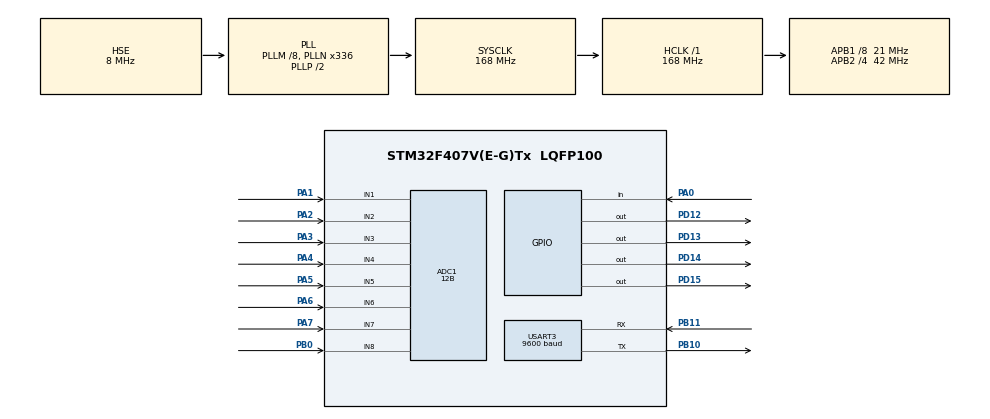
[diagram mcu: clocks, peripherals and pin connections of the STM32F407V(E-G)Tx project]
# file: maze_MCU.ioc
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ADC1.Channel-0\#ChannelRegularConversion=ADC_CHANNEL_1
ADC1.Channel-1\#ChannelRegularConversion=ADC_CHANNEL_2
ADC1.Channel-10\#ChannelRegularConversion=ADC_CHANNEL_6
ADC1.Channel-11\#ChannelRegularConversion=ADC_CHANNEL_7
ADC1.Channel-12\#ChannelRegularConversion=ADC_CHANNEL_8
ADC1.Channel-14\#ChannelRegularConversion=ADC_CHANNEL_1
ADC1.Channel-15\#ChannelRegularConversion=ADC_CHANNEL_1
ADC1.Channel-16\#ChannelRegularConversion=ADC_CHANNEL_1
ADC1.Channel-17\#ChannelRegularConversion=ADC_CHANNEL_1
ADC1.Channel-18\#ChannelRegularConversion=ADC_CHANNEL_1
ADC1.Channel-19\#ChannelRegularConversion=ADC_CHANNEL_1
ADC1.Channel-2\#ChannelRegularConversion=ADC_CHANNEL_3
ADC1.Channel-20\#ChannelRegularConversion=ADC_CHANNEL_1
ADC1.Channel-21\#ChannelRegularConversion=ADC_CHANNEL_1
ADC1.Channel-22\#ChannelRegularConversion=ADC_CHANNEL_1
ADC1.Channel-23\#ChannelRegularConversion=ADC_CHANNEL_1
ADC1.Channel-8\#ChannelRegularConversion=ADC_CHANNEL_4
ADC1.Channel-9\#ChannelRegularConversion=ADC_CHANNEL_5
ADC1.ClockPrescaler=ADC_CLOCK_SYNC_PCLK_DIV2
ADC1.ContinuousConvMode=ENABLE
ADC1.DMAContinuousRequests=ENABLE
ADC1.DataAlign=ADC_DATAALIGN_RIGHT
ADC1.DiscontinuousConvMode=DISABLE
ADC1.EOCSelection=ADC_EOC_SEQ_CONV
ADC1.EnableAnalogWatchDog=false
ADC1.ExternalTrigConv=ADC_SOFTWARE_START
ADC1.ExternalTrigConvEdge=ADC_EXTERNALTRIGCONVEDGE_NONE
ADC1.InjNumberOfConversion=0
ADC1.NbrOfConversion=8
ADC1.NbrOfConversionFlag=1
ADC1.Rank-0\#ChannelRegularConversion=1
ADC1.Rank-1\#ChannelRegularConversion=2
ADC1.Rank-10\#ChannelRegularConversion=6
ADC1.Rank-11\#ChannelRegularConversion=7
ADC1.Rank-12\#ChannelRegularConversion=8
ADC1.Rank-14\#ChannelRegularConversion=8
ADC1.Rank-15\#ChannelRegularConversion=9
ADC1.Rank-16\#ChannelRegularConversion=9
ADC1.Rank-17\#ChannelRegularConversion=10
ADC1.Rank-18\#ChannelRegularConversion=11
ADC1.Rank-19\#ChannelRegularConversion=12
ADC1.Rank-2\#ChannelRegularConversion=3
ADC1.Rank-20\#ChannelRegularConversion=13
ADC1.Rank-21\#ChannelRegularConversion=14
ADC1.Rank-22\#ChannelRegularConversion=15
ADC1.Rank-23\#ChannelRegularConversion=16
ADC1.Rank-8\#ChannelRegularConversion=4
ADC1.Rank-9\#ChannelRegularConversion=5
ADC1.Resolution=ADC_RESOLUTION_12B
ADC1.SamplingTime-0\#ChannelRegularConversion=ADC_SAMPLETIME_84CYCLES
ADC1.SamplingTime-1\#ChannelRegularConversion=ADC_SAMPLETIME_84CYCLES
ADC1.SamplingTime-10\#ChannelRegularConversion=ADC_SAMPLETIME_84CYCLES
ADC1.SamplingTime-11\#ChannelRegularConversion=ADC_SAMPLETIME_84CYCLES
ADC1.SamplingTime-12\#ChannelRegularConversion=ADC_SAMPLETIME_84CYCLES
ADC1.SamplingTime-14\#ChannelRegularConversion=ADC_SAMPLETIME_3CYCLES
ADC1.SamplingTime-15\#ChannelRegularConversion=ADC_SAMPLETIME_3CYCLES
ADC1.SamplingTime-16\#ChannelRegularConversion=ADC_SAMPLETIME_3CYCLES
ADC1.SamplingTime-17\#ChannelRegularConversion=ADC_SAMPLETIME_3CYCLES
ADC1.SamplingTime-18\#ChannelRegularConversion=ADC_SAMPLETIME_3CYCLES
ADC1.SamplingTime-19\#ChannelRegularConversion=ADC_SAMPLETIME_3CYCLES
ADC1.SamplingTime-2\#ChannelRegularConversion=ADC_SAMPLETIME_84CYCLES
ADC1.SamplingTime-20\#ChannelRegularConversion=ADC_SAMPLETIME_3CYCLES
ADC1.SamplingTime-21\#ChannelRegularConversion=ADC_SAMPLETIME_3CYCLES
ADC1.SamplingTime-22\#ChannelRegularConversion=ADC_SAMPLETIME_3CYCLES
ADC1.SamplingTime-23\#ChannelRegularConversion=ADC_SAMPLETIME_3CYCLES
ADC1.SamplingTime-8\#ChannelRegularConversion=ADC_SAMPLETIME_84CYCLES
ADC1.SamplingTime-9\#ChannelRegularConversion=ADC_SAMPLETIME_84CYCLES
ADC1.ScanConvMode=ENABLE
ADC1.master=1
Dma.ADC1.0.Direction=DMA_PERIPH_TO_MEMORY
Dma.ADC1.0.FIFOMode=DMA_FIFOMODE_DISABLE
Dma.ADC1.0.Instance=DMA2_Stream0
Dma.ADC1.0.MemDataAlignment=DMA_MDATAALIGN_WORD
Dma.ADC1.0.MemInc=DMA_MINC_ENABLE
Dma.ADC1.0.Mode=DMA_CIRCULAR
Dma.ADC1.0.PeriphDataAlignment=DMA_PDATAALIGN_WORD
Dma.ADC1.0.PeriphInc=DMA_PINC_DISABLE
Dma.ADC1.0.Priority=DMA_PRIORITY_LOW
Dma.Request0=ADC1
Mcu.Family=STM32F4
Mcu.Name=STM32F407V(E-G)Tx
Mcu.Package=LQFP100
NVIC.ADC_IRQn=true\:0\:0\:false\:false\:true\:true
NVIC.DMA2_Stream0_IRQn=true\:0\:0\:false\:false\:true\:false
NVIC.PriorityGroup=NVIC_PRIORITYGROUP_4
NVIC.USART3_IRQn=true\:0\:0\:false\:false\:true\:true
PA0-WKUP.Signal=GPIO_Input
PA1.Signal=ADCx_IN1
PA2.Signal=ADCx_IN2
PA3.Signal=ADCx_IN3
PA4.Signal=ADCx_IN4
PA5.Signal=ADCx_IN5
PA6.Signal=ADCx_IN6
PA7.Signal=ADCx_IN7
PB0.Signal=ADCx_IN8
PB10.Mode=Asynchronous
PB10.Signal=USART3_TX
PB11.Mode=Asynchronous
PB11.Signal=USART3_RX
PD12.Signal=GPIO_Output
PD13.Signal=GPIO_Output
PD14.Signal=GPIO_Output
PD15.Signal=GPIO_Output
PH0-OSC_IN.Mode=HSE-External-Oscillator
PH0-OSC_IN.Signal=RCC_OSC_IN
PH1-OSC_OUT.Mode=HSE-External-Oscillator
PH1-OSC_OUT.Signal=RCC_OSC_OUT
ProjectManager.HeapSize=0x200
ProjectManager.StackSize=0x400
ProjectManager.TargetToolchain=MDK-ARM V5
RCC.48MHZClocksFreq_Value=84000000
RCC.AHBFreq_Value=168000000
RCC.APB1CLKDivider=RCC_HCLK_DIV8
RCC.APB1Freq_Value=21000000
RCC.APB1TimFreq_Value=42000000
RCC.APB2CLKDivider=RCC_HCLK_DIV4
RCC.APB2Freq_Value=42000000
RCC.APB2TimFreq_Value=84000000
RCC.CortexFreq_Value=168000000
RCC.HCLKFreq_Value=168000000
RCC.HSE_VALUE=8000000
RCC.HSI_VALUE=16000000
RCC.LSE_VALUE=32768
RCC.PLLM=8
RCC.PLLN=336
RCC.PLLSourceVirtual=RCC_PLLSOURCE_HSE
RCC.SYSCLKFreq_VALUE=168000000
RCC.SYSCLKSource=RCC_SYSCLKSOURCE_PLLCLK
RCC.VCOOutputFreq_Value=336000000
SH.ADCx_IN1.0=ADC1_IN1,IN1
SH.ADCx_IN2.0=ADC1_IN2,IN2
SH.ADCx_IN3.0=ADC1_IN3,IN3
SH.ADCx_IN4.0=ADC1_IN4,IN4
SH.ADCx_IN5.0=ADC1_IN5,IN5
SH.ADCx_IN6.0=ADC1_IN6,IN6
SH.ADCx_IN7.0=ADC1_IN7,IN7
SH.ADCx_IN8.0=ADC1_IN8,IN8
USART3.BaudRate=9600
USART3.VirtualMode=VM_ASYNC
board=maze_MCU

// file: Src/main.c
/**
  ******************************************************************************
  * @file           : main.c
  * @brief          : Main program body
  ******************************************************************************
  ** This notice applies to any and all portions of this file
  * that are not between comment pairs USER CODE BEGIN and
  * USER CODE END. Other portions of this file, whether
  * inserted by the user or by software development tools
  * are owned by their respective copyright owners.
  *
  * COPYRIGHT(c) 2018 STMicroelectronics
  *
  * Redistribution and use in source and binary forms, with or without modification,
  * are permitted provided that the following conditions are met:
  *   1. Redistributions of source code must retain the above copyright notice,
  *      this list of conditions and the following disclaimer.
  *   2. Redistributions in binary form must reproduce the above copyright notice,
  *      this list of conditions and the following disclaimer in the documentation
  *      and/or other materials provided with the distribution.
  *   3. Neither the name of STMicroelectronics nor the names of its contributors
  *      may be used to endorse or promote products derived from this software
  *      without specific prior written permission.
  *
  * THIS SOFTWARE IS PROVIDED BY THE COPYRIGHT HOLDERS AND CONTRIBUTORS "AS IS"
  * AND ANY EXPRESS OR IMPLIED WARRANTIES, INCLUDING, BUT NOT LIMITED TO, THE
  * IMPLIED WARRANTIES OF MERCHANTABILITY AND FITNESS FOR A PARTICULAR PURPOSE ARE
  * DISCLAIMED. IN NO EVENT SHALL THE COPYRIGHT HOLDER OR CONTRIBUTORS BE LIABLE
  * FOR ANY DIRECT, INDIRECT, INCIDENTAL, SPECIAL, EXEMPLARY, OR CONSEQUENTIAL
  * DAMAGES (INCLUDING, BUT NOT LIMITED TO, PROCUREMENT OF SUBSTITUTE GOODS OR
  * SERVICES; LOSS OF USE, DATA, OR PROFITS; OR BUSINESS INTERRUPTION) HOWEVER
  * CAUSED AND ON ANY THEORY OF LIABILITY, WHETHER IN CONTRACT, STRICT LIABILITY,
  * OR TORT (INCLUDING NEGLIGENCE OR OTHERWISE) ARISING IN ANY WAY OUT OF THE USE
  * OF THIS SOFTWARE, EVEN IF ADVISED OF THE POSSIBILITY OF SUCH DAMAGE.
  *
  ******************************************************************************
  */

/* 1.
 *
 */
/* 1. white and dark object has ~4 units difference of reflection.
 *
 */
#include "main.h"
#include "stm32f4xx_hal.h"

#define SysTickIT_500us 2000

/* USER CODE BEGIN Includes */
#include "maze.h"
#include "esp8266.h"
#include "uart_maze.h"
/* USER CODE END Includes */
int g_test;
ADC_HandleTypeDef hadc1;
DMA_HandleTypeDef hdma_adc1;
UART_HandleTypeDef huart3;

/* USER CODE BEGIN PV */
/* Private variables ---------------------------------------------------------*/
//bool calibrating = true;
__IO uint32_t ADC_BUF[8];
__IO uint8_t chIndex = 0;
__IO UART UART_esp8266 = {STANDBY, &huart3, INIT, 0, 0, NO};
/* USER CODE END PV */

void SystemClock_Config(void);
static void MX_GPIO_Init(void);
static void MX_USART3_UART_Init(void);
static void MX_ADC1_Init(void);

/* USER CODE BEGIN PFP */
/* Private function prototypes -----------------------------------------------*/

/* USER CODE END PFP */

/* USER CODE BEGIN 0 */
void HAL_ADC_ConvCpltCallback(ADC_HandleTypeDef* hadc)
{
  if (hadc->Instance == ADC1 && chIndex == 0)
    ADC_BUF[0] = HAL_ADC_GetValue(hadc);
  else if (hadc->Instance == ADC1 && chIndex == 1)
    ADC_BUF[1] = HAL_ADC_GetValue(hadc);
  else if (hadc->Instance == ADC1 && chIndex == 2)
    ADC_BUF[2] = HAL_ADC_GetValue(hadc);
  else if (hadc->Instance == ADC1 && chIndex == 3)
    ADC_BUF[3] = HAL_ADC_GetValue(hadc);
  else if (hadc->Instance == ADC1 && chIndex == 4)
    ADC_BUF[4] = HAL_ADC_GetValue(hadc);
  else if (hadc->Instance == ADC1 && chIndex == 5)
    ADC_BUF[5] = HAL_ADC_GetValue(hadc);
  else if (hadc->Instance == ADC1 && chIndex == 6)
    ADC_BUF[6] = HAL_ADC_GetValue(hadc);
  else if (hadc->Instance == ADC1 && chIndex == 7)
    ADC_BUF[7] = HAL_ADC_GetValue(hadc);
  chIndex++;
  if (chIndex == 8)
    chIndex = 0;
}
/* USER CODE END 0 */

int main(void)
{

  /* MCU Configuration----------------------------------------------------------*/

  /* Reset of all peripherals, Initializes the Flash interface and the Systick. */
  HAL_Init();

  /* Configure the system clock */
  SystemClock_Config();

  /* USER CODE BEGIN SysInit */

  /* USER CODE END SysInit *//*  */

  /* Initialize all configured peripherals */
  MX_GPIO_Init();
  MX_USART3_UART_Init();
  MX_ADC1_Init();
  /* USER CODE BEGIN 2 */
  HAL_ADC_Start_IT(&hadc1);
	Maze_Init();
  uartTransInit();
  /* USER CODE END 2 */
  while (1)
  {
    /* USER CODE END WHILE */
    uartTransmission();
    Maze_Rat_Detect();
  }
}

void SystemClock_Config(void)
{

  RCC_OscInitTypeDef RCC_OscInitStruct;
  RCC_ClkInitTypeDef RCC_ClkInitStruct;

    /**Configure the main internal regulator output voltage
    */
  __HAL_RCC_PWR_CLK_ENABLE();

  __HAL_PWR_VOLTAGESCALING_CONFIG(PWR_REGULATOR_VOLTAGE_SCALE1);

    /**Initializes the CPU, AHB and APB busses clocks
    */
  RCC_OscInitStruct.OscillatorType = RCC_OSCILLATORTYPE_HSE;
  RCC_OscInitStruct.HSEState = RCC_HSE_ON;
  RCC_OscInitStruct.PLL.PLLState = RCC_PLL_ON;
  RCC_OscInitStruct.PLL.PLLSource = RCC_PLLSOURCE_HSE;
  RCC_OscInitStruct.PLL.PLLM = 8;
  RCC_OscInitStruct.PLL.PLLN = 336;
  RCC_OscInitStruct.PLL.PLLP = RCC_PLLP_DIV2;
  RCC_OscInitStruct.PLL.PLLQ = 4;
  if (HAL_RCC_OscConfig(&RCC_OscInitStruct) != HAL_OK)
  {
    _Error_Handler(__FILE__, __LINE__);
  }

    /**Initializes the CPU, AHB and APB busses clocks
    */
  RCC_ClkInitStruct.ClockType = RCC_CLOCKTYPE_HCLK|RCC_CLOCKTYPE_SYSCLK
                              |RCC_CLOCKTYPE_PCLK1|RCC_CLOCKTYPE_PCLK2;
  RCC_ClkInitStruct.SYSCLKSource = RCC_SYSCLKSOURCE_PLLCLK;
  RCC_ClkInitStruct.AHBCLKDivider = RCC_SYSCLK_DIV1;
  RCC_ClkInitStruct.APB1CLKDivider = RCC_HCLK_DIV8;
  RCC_ClkInitStruct.APB2CLKDivider = RCC_HCLK_DIV4;

  if (HAL_RCC_ClockConfig(&RCC_ClkInitStruct, FLASH_LATENCY_5) != HAL_OK)
  {
    _Error_Handler(__FILE__, __LINE__);
  }

    /**Configure the Systick interrupt time
    */
  HAL_SYSTICK_Config(HAL_RCC_GetHCLKFreq()/1000);//SysTickIT_500us);

    /**Configure the Systick
    */
  HAL_SYSTICK_CLKSourceConfig(SYSTICK_CLKSOURCE_HCLK);

  /* SysTick_IRQn interrupt configuration */
  HAL_NVIC_SetPriority(SysTick_IRQn, 0, 0);
}

/* ADC1 init function */
static void MX_ADC1_Init(void)
{

  ADC_ChannelConfTypeDef sConfig;

    /**Configure the global features of the ADC (Clock, Resolution, Data Alignment and number of conversion)
    */
  hadc1.Instance = ADC1;
  hadc1.Init.ClockPrescaler = ADC_CLOCK_SYNC_PCLK_DIV2;
  hadc1.Init.Resolution = ADC_RESOLUTION_8B;
  hadc1.Init.ScanConvMode = ENABLE;
  hadc1.Init.ContinuousConvMode = ENABLE;
  hadc1.Init.DiscontinuousConvMode = DISABLE;
  hadc1.Init.ExternalTrigConvEdge = ADC_EXTERNALTRIGCONVEDGE_NONE;
  hadc1.Init.ExternalTrigConv = ADC_SOFTWARE_START;
  hadc1.Init.DataAlign = ADC_DATAALIGN_RIGHT;
  hadc1.Init.NbrOfConversion = 8;
  hadc1.Init.DMAContinuousRequests = DISABLE;
  hadc1.Init.EOCSelection = ADC_EOC_SINGLE_CONV;//DISABLE;//ADC_EOC_SINGLE_CONV;
  if (HAL_ADC_Init(&hadc1) != HAL_OK)
  {
    _Error_Handler(__FILE__, __LINE__);
  }

    /**Configure for the selected ADC regular channel its corresponding rank in the sequencer and its sample time.
    */
  sConfig.Channel = ADC_CHANNEL_14;
  sConfig.Rank = 1;
  sConfig.SamplingTime = ADC_SAMPLETIME_144CYCLES;
  if (HAL_ADC_ConfigChannel(&hadc1, &sConfig) != HAL_OK)
  {
    _Error_Handler(__FILE__, __LINE__);
  }

    /**Configure for the selected ADC regular channel its corresponding rank in the sequencer and its sample time.
    */
  sConfig.Channel = ADC_CHANNEL_13;
  sConfig.Rank = 2;
  if (HAL_ADC_ConfigChannel(&hadc1, &sConfig) != HAL_OK)
  {
    _Error_Handler(__FILE__, __LINE__);
  }

    /**Configure for the selected ADC regular channel its corresponding rank in the sequencer and its sample time.
    */
  sConfig.Channel = ADC_CHANNEL_2;
  sConfig.Rank = 3;
  if (HAL_ADC_ConfigChannel(&hadc1, &sConfig) != HAL_OK)
  {
    _Error_Handler(__FILE__, __LINE__);
  }

    /**Configure for the selected ADC regular channel its corresponding rank in the sequencer and its sample time.
    */
  sConfig.Channel = ADC_CHANNEL_1;
  sConfig.Rank = 4;
  if (HAL_ADC_ConfigChannel(&hadc1, &sConfig) != HAL_OK)
  {
    _Error_Handler(__FILE__, __LINE__);
  }

    /**Configure for the selected ADC regular channel its corresponding rank in the sequencer and its sample time.
    */
  sConfig.Channel = ADC_CHANNEL_4;
  sConfig.Rank = 5;
  if (HAL_ADC_ConfigChannel(&hadc1, &sConfig) != HAL_OK)
  {
    _Error_Handler(__FILE__, __LINE__);
  }

    /**Configure for the selected ADC regular channel its corresponding rank in the sequencer and its sample time.
    */
  sConfig.Channel = ADC_CHANNEL_9;
  sConfig.Rank = 6;
  if (HAL_ADC_ConfigChannel(&hadc1, &sConfig) != HAL_OK)
  {
    _Error_Handler(__FILE__, __LINE__);
  }

    /**Configure for the selected ADC regular channel its corresponding rank in the sequencer and its sample time.
    */
  sConfig.Channel = ADC_CHANNEL_15;
  sConfig.Rank = 7;
  if (HAL_ADC_ConfigChannel(&hadc1, &sConfig) != HAL_OK)
  {
    _Error_Handler(__FILE__, __LINE__);
  }

    /**Configure for the selected ADC regular channel its corresponding rank in the sequencer and its sample time.
    */
  sConfig.Channel = ADC_CHANNEL_3;
  sConfig.Rank = 8;
  if (HAL_ADC_ConfigChannel(&hadc1, &sConfig) != HAL_OK)
  {
    _Error_Handler(__FILE__, __LINE__);
  }

}

/* USART3 init function */
static void MX_USART3_UART_Init(void)
{

  huart3.Instance = USART3;
  huart3.Init.BaudRate = 115200;
  huart3.Init.WordLength = UART_WORDLENGTH_8B;
  huart3.Init.StopBits = UART_STOPBITS_1;
  huart3.Init.Parity = UART_PARITY_NONE;
  huart3.Init.Mode = UART_MODE_TX_RX;
  huart3.Init.HwFlowCtl = UART_HWCONTROL_NONE;
  huart3.Init.OverSampling = UART_OVERSAMPLING_16;
  if (HAL_UART_Init(&huart3) != HAL_OK)
  {
    _Error_Handler(__FILE__, __LINE__);
  }

}

/** Configure pins as
        * Analog
        * Input
        * Output
        * EVENT_OUT
        * EXTI
*/
static void MX_GPIO_Init(void)
{

  GPIO_InitTypeDef GPIO_InitStruct;

  /* GPIO Ports Clock Enable */
  __HAL_RCC_GPIOH_CLK_ENABLE();
  __HAL_RCC_GPIOA_CLK_ENABLE();
  __HAL_RCC_GPIOB_CLK_ENABLE();
  __HAL_RCC_GPIOC_CLK_ENABLE();
  __HAL_RCC_GPIOD_CLK_ENABLE();
  __HAL_RCC_GPIOE_CLK_ENABLE();

  /*Configure GPIO pin Output Level */
  HAL_GPIO_WritePin(GPIOD, GPIO_PIN_12|GPIO_PIN_13|GPIO_PIN_14|GPIO_PIN_15, GPIO_PIN_RESET);

  /*Configure GPIO pin : PA0 */
  GPIO_InitStruct.Pin = GPIO_PIN_0;
  GPIO_InitStruct.Mode = GPIO_MODE_INPUT;
  GPIO_InitStruct.Pull = GPIO_NOPULL;
  HAL_GPIO_Init(GPIOA, &GPIO_InitStruct);

  /*Configure GPIO pin : PE4 */
  GPIO_InitStruct.Pin = GPIO_PIN_4;
  GPIO_InitStruct.Mode = GPIO_MODE_INPUT;
  GPIO_InitStruct.Pull = GPIO_PULLUP;
  HAL_GPIO_Init(GPIOE, &GPIO_InitStruct);

  /*Configure GPIO pins : PD12 PD13 PD14 PD15 */
  GPIO_InitStruct.Pin = GPIO_PIN_12|GPIO_PIN_13|GPIO_PIN_14|GPIO_PIN_15;
  GPIO_InitStruct.Mode = GPIO_MODE_OUTPUT_PP;
  GPIO_InitStruct.Pull = GPIO_NOPULL;
  GPIO_InitStruct.Speed = GPIO_SPEED_FREQ_LOW;
  HAL_GPIO_Init(GPIOD, &GPIO_InitStruct);

}

void _Error_Handler(char *file, int line)
{
  while(1)
  {
  }
}

/************************ (C) COPYRIGHT STMicroelectronics *****END OF FILE****/
